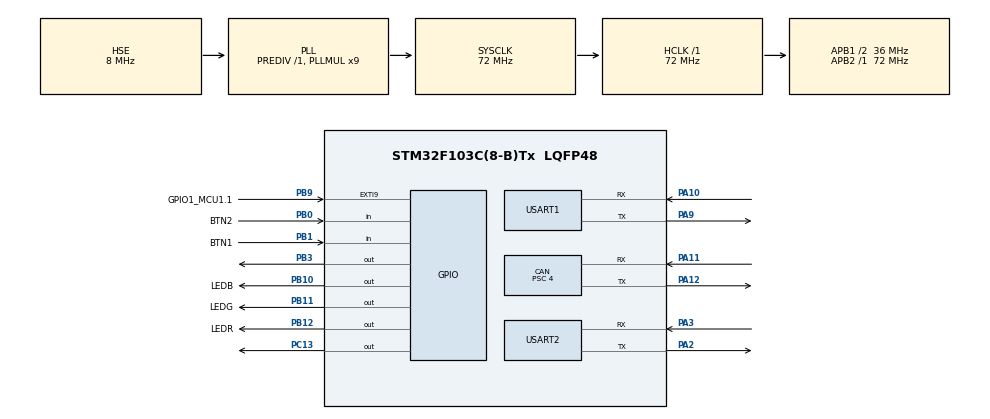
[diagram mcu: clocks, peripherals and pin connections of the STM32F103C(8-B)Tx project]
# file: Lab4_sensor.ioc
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CAN.BS1=CAN_BS1_13TQ
CAN.BS2=CAN_BS2_4TQ
CAN.CalculateBaudRate=500000
CAN.CalculateTimeBit=2000
CAN.CalculateTimeQuantum=111.11111111111111
CAN.Prescaler=4
CAN.SJW=CAN_SJW_2TQ
Mcu.Family=STM32F1
Mcu.Name=STM32F103C(8-B)Tx
Mcu.Package=LQFP48
NVIC.CAN1_RX1_IRQn=true\:0\:0\:false\:false\:true\:true\:true\:true
NVIC.PriorityGroup=NVIC_PRIORITYGROUP_4
NVIC.TIM2_IRQn=true\:0\:0\:false\:false\:true\:true\:true\:true
PA10.Mode=Asynchronous
PA10.Signal=USART1_RX
PA11.Mode=CAN_Activate
PA11.Signal=CAN_RX
PA12.Mode=CAN_Activate
PA12.Signal=CAN_TX
PA13.Mode=Serial_Wire
PA13.Signal=SYS_JTMS-SWDIO
PA14.Mode=Serial_Wire
PA14.Signal=SYS_JTCK-SWCLK
PA2.Mode=Asynchronous
PA2.Signal=USART2_TX
PA3.Mode=Asynchronous
PA3.Signal=USART2_RX
PA9.Mode=Asynchronous
PA9.Signal=USART1_TX
PB0.GPIO_Label=BTN2
PB0.Signal=GPIO_Input
PB1.GPIO_Label=BTN1
PB1.Signal=GPIO_Input
PB10.GPIO_Label=LEDB
PB10.PinState=GPIO_PIN_SET
PB10.Signal=GPIO_Output
PB11.GPIO_Label=LEDG
PB11.PinState=GPIO_PIN_SET
PB11.Signal=GPIO_Output
PB12.GPIO_Label=LEDR
PB12.PinState=GPIO_PIN_SET
PB12.Signal=GPIO_Output
PB3.PinState=GPIO_PIN_SET
PB3.Signal=GPIO_Output
PB9.GPIO_Label=GPIO1_MCU1.1
PB9.Signal=GPXTI9
PC13-TAMPER-RTC.Signal=GPIO_Output
PD0-OSC_IN.Mode=HSE-External-Oscillator
PD0-OSC_IN.Signal=RCC_OSC_IN
PD1-OSC_OUT.Mode=HSE-External-Oscillator
PD1-OSC_OUT.Signal=RCC_OSC_OUT
ProjectManager.HeapSize=0x200
ProjectManager.StackSize=0x400
ProjectManager.TargetToolchain=STM32CubeIDE
RCC.ADCPresc=RCC_ADCPCLK2_DIV6
RCC.AHBFreq_Value=72000000
RCC.APB1CLKDivider=RCC_HCLK_DIV2
RCC.APB1Freq_Value=36000000
RCC.APB1TimFreq_Value=72000000
RCC.APB2Freq_Value=72000000
RCC.APB2TimFreq_Value=72000000
RCC.HCLKFreq_Value=72000000
RCC.PLLMUL=RCC_PLL_MUL9
RCC.PLLSourceVirtual=RCC_PLLSOURCE_HSE
RCC.SYSCLKFreq_VALUE=72000000
RCC.SYSCLKSource=RCC_SYSCLKSOURCE_PLLCLK
RCC.USBFreq_Value=72000000
TIM2.Period=999
TIM2.Prescaler=3599
USART1.VirtualMode=VM_ASYNC
USART2.VirtualMode=VM_ASYNC
VP_TIM2_VS_ClockSourceINT.Mode=Internal
board=custom

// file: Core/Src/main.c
/* USER CODE BEGIN Header */
/**
  ******************************************************************************
  * @file           : main.c
  * @brief          : Main program body
  ******************************************************************************
  * @attention
  *
  * Copyright (c) 2023 STMicroelectronics.
  * All rights reserved.
  *
  * This software is licensed under terms that can be found in the LICENSE file
  * in the root directory of this software component.
  * If no LICENSE file comes with this software, it is provided AS-IS.
  *
  ******************************************************************************
  */
/* USER CODE END Header */
#include "main.h"
#include "canbus.h"

CAN_HandleTypeDef hcan;

TIM_HandleTypeDef htim2;

UART_HandleTypeDef huart1;
UART_HandleTypeDef huart2;

/* USER CODE BEGIN PV */
extern uint8_t RxBuffer[];
extern uint8_t DiagnosticFlag;
extern CAN_RxHeaderTypeDef RxHeader;
/* USER CODE END PV */

void SystemClock_Config(void);
static void MX_GPIO_Init(void);
static void MX_CAN_Init(void);
static void MX_USART1_UART_Init(void);
static void MX_USART2_UART_Init(void);
static void MX_TIM2_Init(void);

int main(void)
{

  /* MCU Configuration--------------------------------------------------------*/

  /* Reset of all peripherals, Initializes the Flash interface and the Systick. */
  HAL_Init();

  /* Configure the system clock */
  SystemClock_Config();

  /* Initialize all configured peripherals */
  MX_GPIO_Init();
  MX_CAN_Init();
  MX_USART1_UART_Init();
  MX_USART2_UART_Init();
  MX_TIM2_Init();
  /* USER CODE BEGIN 2 */
  if (HAL_CAN_Start(&hcan) != HAL_OK)
  {
	  Error_Handler();
  }
  HAL_CAN_ActivateNotification(&hcan, CAN_IT_RX_FIFO1_MSG_PENDING);
  /* USER CODE END 2 */

  /* Infinite loop */
  while (1)
  {
	  ReadDataByIdentifierRequest(&hcan);

	  //WriteShortDataByIdentifierRequest(&hcan);
	  //SecurityAccessRequest(&hcan);
	  	while (DiagnosticFlag != 1)
	  	{
	  		DiagnosticFlag = 0;
	  	ReadDataByIdentifierResponse(RxBuffer);
	  //	WriteDataByIdenfierResponse(RxBuffer);
	  	//	if (SecurityAccessSeedResponse(RxBuffer))
	  	//	{
	  	//		while (DiagnosticFlag != 1)
	  	//		{
	  	//				DiagnosticFlag = 0;
	  	//				HAL_GPIO_TogglePin(GPIOB, LEDB_Pin);
	  	//				UnlockRequest(&hcan);
	  	//				while (DiagnosticFlag != 1);
	  	//				DiagnosticFlag = 0;
	  	//		}
	  	//	}
  }
}
}

void SystemClock_Config(void)
{
  RCC_OscInitTypeDef RCC_OscInitStruct = {0};
  RCC_ClkInitTypeDef RCC_ClkInitStruct = {0};

  /** Initializes the RCC Oscillators according to the specified parameters
  * in the RCC_OscInitTypeDef structure.
  */
  RCC_OscInitStruct.OscillatorType = RCC_OSCILLATORTYPE_HSE;
  RCC_OscInitStruct.HSEState = RCC_HSE_ON;
  RCC_OscInitStruct.HSEPredivValue = RCC_HSE_PREDIV_DIV1;
  RCC_OscInitStruct.HSIState = RCC_HSI_ON;
  RCC_OscInitStruct.PLL.PLLState = RCC_PLL_ON;
  RCC_OscInitStruct.PLL.PLLSource = RCC_PLLSOURCE_HSE;
  RCC_OscInitStruct.PLL.PLLMUL = RCC_PLL_MUL9;
  if (HAL_RCC_OscConfig(&RCC_OscInitStruct) != HAL_OK)
  {
    Error_Handler();
  }

  /** Initializes the CPU, AHB and APB buses clocks
  */
  RCC_ClkInitStruct.ClockType = RCC_CLOCKTYPE_HCLK|RCC_CLOCKTYPE_SYSCLK
                              |RCC_CLOCKTYPE_PCLK1|RCC_CLOCKTYPE_PCLK2;
  RCC_ClkInitStruct.SYSCLKSource = RCC_SYSCLKSOURCE_PLLCLK;
  RCC_ClkInitStruct.AHBCLKDivider = RCC_SYSCLK_DIV1;
  RCC_ClkInitStruct.APB1CLKDivider = RCC_HCLK_DIV2;
  RCC_ClkInitStruct.APB2CLKDivider = RCC_HCLK_DIV1;

  if (HAL_RCC_ClockConfig(&RCC_ClkInitStruct, FLASH_LATENCY_2) != HAL_OK)
  {
    Error_Handler();
  }
}

static void MX_CAN_Init(void)
{

  hcan.Instance = CAN1;
  hcan.Init.Prescaler = 4;
  hcan.Init.Mode = CAN_MODE_NORMAL;
  hcan.Init.SyncJumpWidth = CAN_SJW_2TQ;
  hcan.Init.TimeSeg1 = CAN_BS1_13TQ;
  hcan.Init.TimeSeg2 = CAN_BS2_4TQ;
  hcan.Init.TimeTriggeredMode = DISABLE;
  hcan.Init.AutoBusOff = DISABLE;
  hcan.Init.AutoWakeUp = DISABLE;
  hcan.Init.AutoRetransmission = DISABLE;
  hcan.Init.ReceiveFifoLocked = DISABLE;
  hcan.Init.TransmitFifoPriority = DISABLE;
  if (HAL_CAN_Init(&hcan) != HAL_OK)
  {
    Error_Handler();
  }

}

static void MX_TIM2_Init(void)
{

  TIM_ClockConfigTypeDef sClockSourceConfig = {0};
  TIM_MasterConfigTypeDef sMasterConfig = {0};

  htim2.Instance = TIM2;
  htim2.Init.Prescaler = 3599;
  htim2.Init.CounterMode = TIM_COUNTERMODE_UP;
  htim2.Init.Period = 999;
  htim2.Init.ClockDivision = TIM_CLOCKDIVISION_DIV1;
  htim2.Init.AutoReloadPreload = TIM_AUTORELOAD_PRELOAD_DISABLE;
  if (HAL_TIM_Base_Init(&htim2) != HAL_OK)
  {
    Error_Handler();
  }
  sClockSourceConfig.ClockSource = TIM_CLOCKSOURCE_INTERNAL;
  if (HAL_TIM_ConfigClockSource(&htim2, &sClockSourceConfig) != HAL_OK)
  {
    Error_Handler();
  }
  sMasterConfig.MasterOutputTrigger = TIM_TRGO_RESET;
  sMasterConfig.MasterSlaveMode = TIM_MASTERSLAVEMODE_DISABLE;
  if (HAL_TIMEx_MasterConfigSynchronization(&htim2, &sMasterConfig) != HAL_OK)
  {
    Error_Handler();
  }

}

static void MX_USART1_UART_Init(void)
{

  huart1.Instance = USART1;
  huart1.Init.BaudRate = 115200;
  huart1.Init.WordLength = UART_WORDLENGTH_8B;
  huart1.Init.StopBits = UART_STOPBITS_1;
  huart1.Init.Parity = UART_PARITY_NONE;
  huart1.Init.Mode = UART_MODE_TX_RX;
  huart1.Init.HwFlowCtl = UART_HWCONTROL_NONE;
  huart1.Init.OverSampling = UART_OVERSAMPLING_16;
  if (HAL_UART_Init(&huart1) != HAL_OK)
  {
    Error_Handler();
  }

}

static void MX_USART2_UART_Init(void)
{

  huart2.Instance = USART2;
  huart2.Init.BaudRate = 115200;
  huart2.Init.WordLength = UART_WORDLENGTH_8B;
  huart2.Init.StopBits = UART_STOPBITS_1;
  huart2.Init.Parity = UART_PARITY_NONE;
  huart2.Init.Mode = UART_MODE_TX_RX;
  huart2.Init.HwFlowCtl = UART_HWCONTROL_NONE;
  huart2.Init.OverSampling = UART_OVERSAMPLING_16;
  if (HAL_UART_Init(&huart2) != HAL_OK)
  {
    Error_Handler();
  }

}

static void MX_GPIO_Init(void)
{
  GPIO_InitTypeDef GPIO_InitStruct = {0};

  /* GPIO Ports Clock Enable */
  __HAL_RCC_GPIOC_CLK_ENABLE();
  __HAL_RCC_GPIOD_CLK_ENABLE();
  __HAL_RCC_GPIOA_CLK_ENABLE();
  __HAL_RCC_GPIOB_CLK_ENABLE();

  /*Configure GPIO pin Output Level */
  HAL_GPIO_WritePin(GPIOC, GPIO_PIN_13, GPIO_PIN_RESET);

  /*Configure GPIO pin Output Level */
  HAL_GPIO_WritePin(GPIOB, LEDB_Pin|LEDG_Pin|LEDR_Pin|GPIO_PIN_3, GPIO_PIN_SET);

  /*Configure GPIO pin : PC13 */
  GPIO_InitStruct.Pin = GPIO_PIN_13;
  GPIO_InitStruct.Mode = GPIO_MODE_OUTPUT_PP;
  GPIO_InitStruct.Pull = GPIO_NOPULL;
  GPIO_InitStruct.Speed = GPIO_SPEED_FREQ_LOW;
  HAL_GPIO_Init(GPIOC, &GPIO_InitStruct);

  /*Configure GPIO pins : BTN2_Pin BTN1_Pin */
  GPIO_InitStruct.Pin = BTN2_Pin|BTN1_Pin;
  GPIO_InitStruct.Mode = GPIO_MODE_INPUT;
  GPIO_InitStruct.Pull = GPIO_NOPULL;
  HAL_GPIO_Init(GPIOB, &GPIO_InitStruct);

  /*Configure GPIO pins : LEDB_Pin LEDG_Pin LEDR_Pin PB3 */
  GPIO_InitStruct.Pin = LEDB_Pin|LEDG_Pin|LEDR_Pin|GPIO_PIN_3;
  GPIO_InitStruct.Mode = GPIO_MODE_OUTPUT_PP;
  GPIO_InitStruct.Pull = GPIO_NOPULL;
  GPIO_InitStruct.Speed = GPIO_SPEED_FREQ_LOW;
  HAL_GPIO_Init(GPIOB, &GPIO_InitStruct);

  /*Configure GPIO pin : GPIO1_MCU1_1_Pin */
  GPIO_InitStruct.Pin = GPIO1_MCU1_1_Pin;
  GPIO_InitStruct.Mode = GPIO_MODE_IT_RISING;
  GPIO_InitStruct.Pull = GPIO_NOPULL;
  HAL_GPIO_Init(GPIO1_MCU1_1_GPIO_Port, &GPIO_InitStruct);

}

void Error_Handler(void)
{
  __disable_irq();
  while (1)
  {
  }
}
